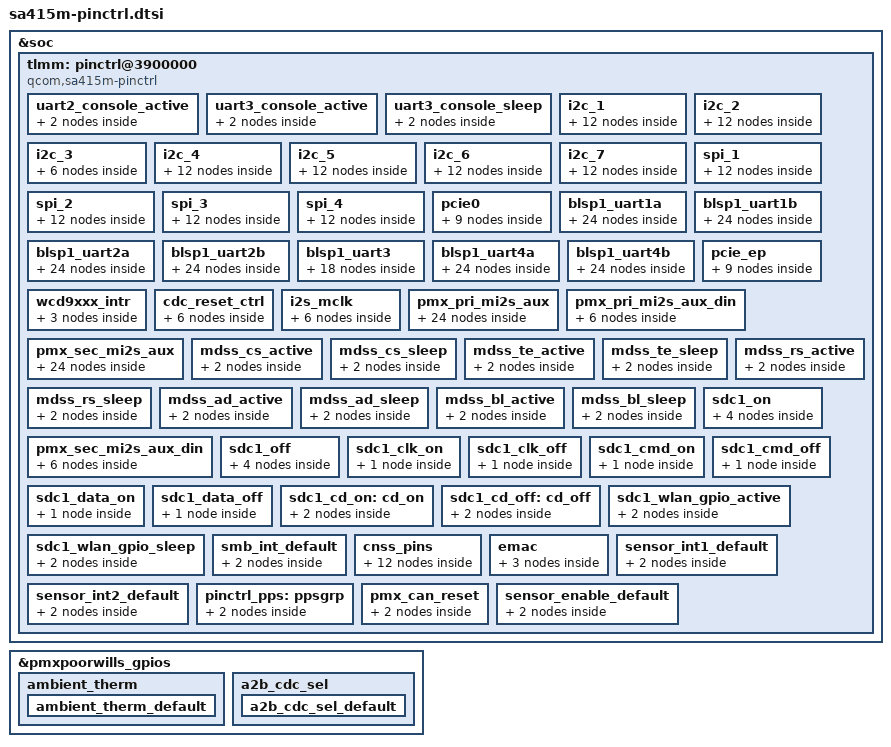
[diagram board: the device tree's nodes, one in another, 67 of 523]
&soc {
	tlmm: pinctrl@3900000 {
		compatible = "qcom,sa415m-pinctrl";
		reg = <0x3900000 0x300000>;
		reg-names = "pinctrl";
		interrupts = <GIC_SPI 212 IRQ_TYPE_LEVEL_HIGH>,
			     <GIC_SPI 213 IRQ_TYPE_LEVEL_HIGH>,
			     <GIC_SPI 214 IRQ_TYPE_LEVEL_HIGH>,
			     <GIC_SPI 215 IRQ_TYPE_LEVEL_HIGH>,
			     <GIC_SPI 216 IRQ_TYPE_LEVEL_HIGH>,
			     <GIC_SPI 217 IRQ_TYPE_LEVEL_HIGH>,
			     <GIC_SPI 218 IRQ_TYPE_LEVEL_HIGH>,
			     <GIC_SPI 219 IRQ_TYPE_LEVEL_HIGH>,
			     <GIC_SPI 220 IRQ_TYPE_LEVEL_HIGH>;
		gpio-controller;
		#gpio-cells = <2>;
		interrupt-controller;
		interrupt-parent = <&intc>;
		#interrupt-cells = <2>;
		wakeup-parent = <&pdc>;

		uart2_console_active: uart2_console_active {
			mux {
				pins = "gpio4", "gpio5";
				function = "blsp_uart2";
			};

			config {
				pins = "gpio4", "gpio5";
				drive-strength = <2>;
				bias-disable;
			};
		};

		uart3_console_active: uart3_console_active {
			mux {
				pins = "gpio8", "gpio9";
				function = "blsp_uart3";
			};

			config {
				pins = "gpio8", "gpio9";
				drive-strength = <2>;
				bias-disable;
			};
		};

		uart3_console_sleep: uart3_console_sleep {
			mux {
				pins = "gpio8", "gpio9";
				function = "gpio";
			};

			config {
				pins = "gpio8", "gpio9";
				drive-strength = <2>;
				bias-disable;
			};
		};

		/* I2C CONFIGURATION */
		i2c_1 {
			i2c_1_sda1_active: i2c_1_sda1_active {
				mux {
					pins = "gpio2";
					function = "blsp_i2c_sda1";
				};

				config {
					pins = "gpio2";
					drive-strength = <2>;
					bias-disable;
				};
			};

			i2c_1_sda1_sleep: i2c_1_sda1_sleep {
				mux {
					pins = "gpio2";
					function = "blsp_i2c_sda1";
				};

				config {
					pins = "gpio2";
					drive-strength = <2>;
					bias-pull-up;
				};
			};

			i2c_1_scl1_active: i2c_1_scl1_active {
				mux {
					pins = "gpio3";
					function = "blsp_i2c_scl1";
				};

				config {
					pins = "gpio3";
					drive-strength = <2>;
					bias-disable;
				};
			};

			i2c_1_scl1_sleep: i2c_1_scl1_sleep {
				mux {
					pins = "gpio3";
					function = "blsp_i2c_scl1";
				};

				config {
					pins = "gpio3";
					drive-strength = <2>;
					bias-pull-up;
				};
			};
		};

		i2c_2 {
			i2c_2_sda2_active: i2c_2_sda2_active {
				mux {
					pins = "gpio6";
					function = "blsp_i2c_sda2";
				};

				config {
					pins = "gpio6";
					drive-strength = <2>;
					bias-disable;
				};
			};

			i2c_2_sda2_sleep: i2c_2_sda2_sleep {
				mux {
					pins = "gpio6";
					function = "blsp_i2c_sda2";
				};

				config {
					pins = "gpio6";
					drive-strength = <2>;
					bias-pull-up;
				};
			};

			i2c_2_scl2_active: i2c_2_scl2_active {
				mux {
					pins = "gpio7";
					function = "blsp_i2c_scl2";
				};

				config {
					pins = "gpio7";
					drive-strength = <2>;
					bias-disable;
				};
			};

			i2c_2_scl2_sleep: i2c_2_scl2_sleep {
				mux {
					pins = "gpio7";
					function = "blsp_i2c_scl2";
				};

				config {
					pins = "gpio7";
					drive-strength = <2>;
					bias-pull-up;
				};
			};
		};

		i2c_3 {
			i2c_3_active: i2c_3_active {
				mux {
					pins = "gpio10", "gpio11";
					function = "blsp_i2c3";
				};

				config {
					pins = "gpio10", "gpio11";
					drive-strength = <2>;
					bias-disable;
				};
			};

			i2c_3_sleep: i2c_3_sleep {
				mux {
					pins = "gpio10", "gpio11";
					function = "blsp_i2c3";
				};

				config {
					pins = "gpio10", "gpio11";
					drive-strength = <2>;
					bias-pull-up;
				};
			};
		};

		i2c_4 {
			i2c_4_sda4_active: i2c_4_sda4_active {
				mux {
					pins = "gpio76";
					function = "blsp_i2c_sda4";
				};

				config {
					pins = "gpio76";
					drive-strength = <2>;
					bias-disable;
				};
			};

			i2c_4_sda4_sleep: i2c_4_sda4_sleep {
				mux {
					pins = "gpio76";
					function = "blsp_i2c_sda4";
				};

				config {
					pins = "gpio76";
					drive-strength = <2>;
					bias-pull-up;
				};
			};

			i2c_4_scl4_active: i2c_4_scl4_active {
				mux {
					pins = "gpio77";
					function = "blsp_i2c_scl4";
				};

				config {
					pins = "gpio77";
					drive-strength = <2>;
					bias-disable;
				};
			};

			i2c_4_scl4_sleep: i2c_4_scl4_sleep {
				mux {
					pins = "gpio77";
					function = "blsp_i2c_scl4";
				};

				config {
					pins = "gpio77";
					drive-strength = <2>;
					bias-pull-up;
				};
			};
		};

		i2c_5 {
			i2c_5_sda1_active: i2c_5_sda1_active {
				mux {
					pins = "gpio74";
					function = "blsp_i2c_sda1";
				};

				config {
					pins = "gpio74";
					drive-strength = <2>;
					bias-disable;
				};
			};

			i2c_5_sda1_sleep: i2c_5_sda1_sleep {
				mux {
					pins = "gpio74";
					function = "blsp_i2c_sda1";
				};

				config {
					pins = "gpio74";
					drive-strength = <2>;
					bias-pull-up;
				};
			};

			i2c_5_scl1_active: i2c_5_scl1_active {
				mux {
					pins = "gpio75";
					function = "blsp_i2c_scl1";
				};

				config {
					pins = "gpio75";
					drive-strength = <2>;
					bias-disable;
				};
			};

			i2c_5_scl1_sleep: i2c_5_scl1_sleep {
				mux {
					pins = "gpio75";
					function = "blsp_i2c_scl1";
				};

				config {
					pins = "gpio75";
					drive-strength = <2>;
					bias-pull-up;
				};
			};
		};

		i2c_6 {
			i2c_6_sda2_active: i2c_6_sda2_active {
				mux {
					pins = "gpio65";
					function = "blsp_i2c_sda2";
				};

				config {
					pins = "gpio65";
					drive-strength = <2>;
					bias-disable;
				};
			};

			i2c_6_sda2_sleep: i2c_6_sda2_sleep {
				mux {
					pins = "gpio65";
					function = "blsp_i2c_sda2";
				};

				config {
					pins = "gpio65";
					drive-strength = <2>;
					bias-pull-up;
				};
			};

			i2c_6_scl2_active: i2c_6_scl2_active {
				mux {
					pins = "gpio66";
					function = "blsp_i2c_scl2";
				};

				config {
					pins = "gpio66";
					drive-strength = <2>;
					bias-disable;
				};
			};

			i2c_6_scl2_sleep: i2c_6_scl2_sleep {
				mux {
					pins = "gpio66";
					function = "blsp_i2c_scl2";
				};

				config {
					pins = "gpio66";
					drive-strength = <2>;
					bias-pull-up;
				};
			};
		};

		i2c_7 {
			i2c_7_sda4_active: i2c_7_sda4_active {
				mux {
					pins = "gpio18";
					function = "blsp_i2c_sda4";
				};

				config {
					pins = "gpio18";
					drive-strength = <2>;
					bias-disable;
				};
			};

			i2c_7_sda4_sleep: i2c_7_sda4_sleep {
				mux {
					pins = "gpio18";
					function = "blsp_i2c_sda4";
				};

				config {
					pins = "gpio18";
					drive-strength = <2>;
					bias-pull-up;
				};
			};

			i2c_7_scl4_active: i2c_7_scl4_active {
				mux {
					pins = "gpio19";
					function = "blsp_i2c_scl4";
				};

				config {
					pins = "gpio19";
					drive-strength = <2>;
					bias-disable;
				};
			};

			i2c_7_scl4_sleep: i2c_7_scl4_sleep {
				mux {
					pins = "gpio19";
					function = "blsp_i2c_scl4";
				};

				config {
					pins = "gpio19";
					drive-strength = <2>;
					bias-pull-up;
				};
			};
		};

		/* SPI CONFIGURATION */
		spi_1 {
			blsp1_active: blsp1_active {
				mux {
					pins = "gpio72", "gpio73",
							"gpio75";
					function = "blsp1";
				};

				config {
					pins = "gpio72", "gpio73",
							"gpio75";
					drive-strength = <6>;
					bias-disable;
				};
			};

			spi_1_cs1_active: spi_1_cs1_active {
				mux {
					pins = "gpio74";
					function = "blsp_spi_cs1";
				};

				config {
					pins = "gpio74";
					drive-strength = <6>;
					bias-disable;
				};
			};

			spi_1_cs1_sleep: spi_1_cs1_sleep {
				mux {
					pins = "gpio74";
					function = "blsp_spi_cs1";
				};

				config {
					pins = "gpio74";
					drive-strength = <6>;
					bias-disable;
				};
			};

			blsp1_sleep: blsp1_sleep {
				mux {
					pins = "gpio72", "gpio73",
							"gpio75";
					function = "blsp1";
				};

				config {
					pins = "gpio72", "gpio73",
							"gpio75";
					drive-strength = <6>;
					bias-disable;
				};
			};
		};

		spi_2 {
			blsp2_active: blsp2_active {
				mux {
					pins = "gpio4", "gpio5",
							"gpio7";
					function = "blsp2";
				};

				config {
					pins = "gpio4", "gpio5",
							"gpio7";
					drive-strength = <6>;
					bias-disable;
				};
			};

			blsp2_sleep: blsp2_sleep {
				mux {
					pins = "gpio4", "gpio5",
							"gpio7";
					function = "blsp2";
				};

				config {
					pins = "gpio4", "gpio5",
							"gpio7";
					drive-strength = <6>;
					bias-disable;
				};
			};

			spi_2_cs2_active: spi_2_cs2_active {
				mux {
					pins = "gpio6";
					function = "blsp_spi_cs2";
				};

				config {
					pins = "gpio6";
					drive-strength = <6>;
					bias-disable;
				};
			};

			spi_2_cs2_sleep: spi_2_cs2_sleep {
				mux {
					pins = "gpio6";
					function = "blsp_spi_cs2";
				};

				config {
					pins = "gpio6";
					drive-strength = <6>;
					bias-disable;
				};
			};
		};

		spi_3 {
			blsp3_active: blsp3_active {
				mux {
					pins = "gpio8", "gpio9",
							"gpio11";
					function = "blsp3";
				};

				config {
					pins = "gpio8", "gpio9",
							"gpio11";
					drive-strength = <6>;
					bias-disable;
				};
			};

			blsp3_sleep: blsp3_sleep {
				mux {
					pins = "gpio8", "gpio9",
							"gpio11";
					function = "blsp3";
				};

				config {
					pins = "gpio8", "gpio9",
							"gpio11";
					drive-strength = <6>;
					bias-disable;
				};
			};

			spi_3_cs3_active: spi_3_cs3_active {
				mux {
					pins = "gpio10";
					function = "blsp_spi_cs3";
				};

				config {
					pins = "gpio10";
					drive-strength = <6>;
					bias-disable;
				};
			};

			spi_3_cs3_sleep: spi_3_cs3_sleep {
				mux {
					pins = "gpio10";
					function = "blsp_spi_cs3";
				};

				config {
					pins = "gpio10";
					drive-strength = <6>;
					bias-disable;
				};
			};
		};

		spi_4 {
			blsp4_active: blsp4_active {
				mux {
					pins = "gpio16", "gpio17",
							"gpio19";
					function = "blsp4";
				};

				config {
					pins = "gpio16", "gpio17",
							"gpio19";
					drive-strength = <6>;
					bias-disable;
				};
			};

			blsp4_sleep: blsp4_sleep {
				mux {
					pins = "gpio16", "gpio17",
							"gpio19";
					function = "blsp4";
				};

				config {
					pins = "gpio16", "gpio17",
							"gpio19";
					drive-strength = <6>;
					bias-disable;
				};
			};

			spi_4_cs4_active: spi_4_cs4_active {
				mux {
					pins = "gpio18";
					function = "blsp_spi_cs4";
				};

				config {
					pins = "gpio18";
					drive-strength = <6>;
					bias-disable;
				};
			};

			spi_4_cs4_sleep: spi_4_cs4_sleep {
				mux {
					pins = "gpio18";
					function = "blsp_spi_cs4";
				};

				config {
					pins = "gpio18";
					drive-strength = <6>;
					bias-disable;
				};
			};
		};

		pcie0 {
			pcie0_clkreq_default: pcie0_clkreq_default {
				mux {
					pins = "gpio56";
					function = "pcie_clkreq";
				};

				config {
					pins = "gpio56";
					drive-strength = <2>;
					bias-pull-up;
				};
			};

			pcie0_perst_default: pcie0_perst_default {
				mux {
					pins = "gpio57";
					function = "gpio";
				};

				config {
					pins = "gpio57";
					drive-strength = <2>;
					bias-pull-down;
				};
			};

			pcie0_wake_default: pcie0_wake_default {
				mux {
					pins = "gpio53";
					function = "gpio";
				};

				config {
					pins = "gpio53";
					drive-strength = <2>;
					bias-pull-up;
				};
			};
		};

		/* HS UART CONFIGURATION */

		blsp1_uart1a: blsp1_uart1a {
			blsp1_uart1a_tx1_active: blsp1_uart1a_tx1_active {
				mux {
					pins = "gpio0";
					function = "blsp_uart_tx1";
				};

				config {
					pins = "gpio0";
					drive-strength = <2>;
					bias-disable;
				};
			};

			blsp1_uart1a_tx1_sleep: blsp1_uart1a_tx1_sleep {
				mux {
					pins = "gpio0";
					function = "blsp_uart_tx1";
				};

				config {
					pins = "gpio0";
					drive-strength = <2>;
					bias-pull-up;
				};
			};

			blsp1_uart1a_rx1_active: blsp1_uart1a_rx1_active {
				mux {
					pins = "gpio1";
					function = "blsp_uart_rx1";
				};

				config {
					pins = "gpio1";
					drive-strength = <2>;
					bias-disable;
				};
			};

			blsp1_uart1a_rx1_sleep: blsp1_uart1a_rx1_sleep {
				mux {
					pins = "gpio1";
					function = "blsp_uart_rx1";
				};

				config {
					pins = "gpio1";
					drive-strength = <2>;
					bias-no-pull;
				};
			};

			blsp1_uart1a_cts1_active: blsp1_uart1a_cts1_active {
				mux {
					pins = "gpio2";
					function = "blsp_uart_cts1";
				};

				config {
					pins = "gpio2";
					drive-strength = <2>;
					bias-disable;
				};
			};

			blsp1_uart1a_cts1_sleep: blsp1_uart1a_cts1_sleep {
				mux {
					pins = "gpio2";
					function = "blsp_uart_cts1";
				};

				config {
					pins = "gpio2";
					drive-strength = <2>;
					bias-no-pull;
				};
			};

			blsp1_uart1a_rfr1_active: blsp1_uart1a_rfr1_active {
				mux {
					pins = "gpio3";
					function = "blsp_uart_rfr1";
				};

				config {
					pins = "gpio3";
					drive-strength = <2>;
					bias-disable;
				};
			};

			blsp1_uart1a_rfr1_sleep: blsp1_uart1a_rfr1_sleep {
				mux {
					pins = "gpio3";
					function = "blsp_uart_rfr1";
				};

				config {
					pins = "gpio3";
					drive-strength = <2>;
					bias-no-pull;
				};
			};
		};

		blsp1_uart1b: blsp1_uart1b {
			blsp1_uart1b_tx1_active: blsp1_uart1b_tx1_active {
				mux {
					pins = "gpio20";
					function = "blsp_uart_tx1";
				};

				config {
					pins = "gpio20";
					drive-strength = <2>;
					bias-disable;
				};
			};

			blsp1_uart1b_tx1_sleep: blsp1_uart1b_tx1_sleep {
				mux {
					pins = "gpio20";
					function = "blsp_uart_tx1";
				};

				config {
					pins = "gpio20";
					drive-strength = <2>;
					bias-pull-up;
				};
			};

			blsp1_uart1b_rx1_active: blsp1_uart1b_rx1_active {
				mux {
					pins = "gpio21";
					function = "blsp_uart_rx1";
				};

				config {
					pins = "gpio21";
					drive-strength = <2>;
					bias-disable;
				};
			};

			blsp1_uart1b_rx1_sleep: blsp1_uart1b_rx1_sleep {
				mux {
					pins = "gpio21";
					function = "blsp_uart_rx1";
				};

				config {
					pins = "gpio21";
					drive-strength = <2>;
					bias-no-pull;
				};
			};

			blsp1_uart1b_cts1_active: blsp1_uart1b_cts1_active {
				mux {
					pins = "gpio22";
					function = "blsp_uart_cts1";
				};

				config {
					pins = "gpio22";
					drive-strength = <2>;
					bias-disable;
				};
			};

			blsp1_uart1b_cts1_sleep: blsp1_uart1b_cts1_sleep {
				mux {
					pins = "gpio22";
					function = "blsp_uart_cts1";
				};

				config {
					pins = "gpio22";
					drive-strength = <2>;
					bias-no-pull;
				};
			};

			blsp1_uart1b_rfr1_active: blsp1_uart1b_rfr1_active {
				mux {
					pins = "gpio23";
					function = "blsp_uart_rfr1";
				};

				config {
					pins = "gpio23";
					drive-strength = <2>;
					bias-disable;
				};
			};

			blsp1_uart1b_rfr1_sleep: blsp1_uart1b_rfr1_sleep {
				mux {
					pins = "gpio23";
					function = "blsp_uart_rfr1";
				};

				config {
					pins = "gpio23";
					drive-strength = <2>;
					bias-no-pull;
				};
			};
		};

		blsp1_uart2a: blsp1_uart2a {
			blsp1_uart2a_tx2_active: blsp1_uart2a_tx2_active {
				mux {
					pins = "gpio4";
					function = "blsp_uart_tx2";
				};

				config {
					pins = "gpio4";
					drive-strength = <2>;
					bias-disable;
				};
			};

			blsp1_uart2a_tx2_sleep: blsp1_uart2a_tx2_sleep {
				mux {
					pins = "gpio4";
					function = "blsp_uart_tx2";
				};

				config {
					pins = "gpio4";
					drive-strength = <2>;
					bias-pull-up;
				};
			};

			blsp1_uart2a_rx2_active: blsp1_uart2a_rx2_active {
				mux {
					pins = "gpio5";
					function = "blsp_uart_rx2";
				};

				config {
					pins = "gpio5";
					drive-strength = <2>;
					bias-disable;
				};
			};

			blsp1_uart2a_rx2_sleep: blsp1_uart2a_rx2_sleep {
				mux {
					pins = "gpio5";
					function = "blsp_uart_rx2";
				};

				config {
					pins = "gpio5";
					drive-strength = <2>;
					bias-disable;
				};
			};

			blsp1_uart2a_cts2_active: blsp1_uart2a_cts2_active {
				mux {
					pins = "gpio6";
					function = "blsp_uart_cts2";
				};

				config {
					pins = "gpio6";
					drive-strength = <2>;
					bias-disable;
				};
			};

			blsp1_uart2a_cts2_sleep: blsp1_uart2a_cts2_sleep {
				mux {
					pins = "gpio6";
					function = "blsp_uart_cts2";
				};

				config {
					pins = "gpio6";
					drive-strength = <2>;
					bias-no-pull;
				};
			};

			blsp1_uart2a_rfr2_active: blsp1_uart2a_rfr2_active {
				mux {
					pins = "gpio7";
					function = "blsp_uart_rfr2";
				};

				config {
					pins = "gpio7";
					drive-strength = <2>;
					bias-disable;
				};
			};

			blsp1_uart2a_rfr2_sleep: blsp1_uart2a_rfr2_sleep {
				mux {
					pins = "gpio7";
					function = "blsp_uart_rfr2";
				};

				config {
					pins = "gpio7";
					drive-strength = <2>;
					bias-no-pull;
				};
			};
		};

		blsp1_uart2b: blsp1_uart2b {
			blsp1_uart2b_tx2_active: blsp1_uart2b_tx2_active {
				mux {
					pins = "gpio63";
					function = "blsp_uart_tx2";
				};

				config {
					pins = "gpio63";
					drive-strength = <2>;
					bias-disable;
				};
			};

			blsp1_uart2b_tx2_sleep: blsp1_uart2b_tx2_sleep {
				mux {
					pins = "gpio63";
					function = "blsp_uart_tx2";
				};

				config {
					pins = "gpio63";
					drive-strength = <2>;
					bias-pull-up;
				};
			};

			blsp1_uart2b_rx2_active: blsp1_uart2b_rx2_active {
				mux {
					pins = "gpio64";
					function = "blsp_uart_rx2";
				};

				config {
					pins = "gpio64";
					drive-strength = <2>;
					bias-disable;
				};
			};

			blsp1_uart2b_rx2_sleep: blsp1_uart2b_rx2_sleep {
				mux {
					pins = "gpio64";
					function = "blsp_uart_rx2";
				};

				config {
					pins = "gpio64";
					drive-strength = <2>;
					bias-no-pull;
				};
			};

			blsp1_uart2b_cts2_active: blsp1_uart2b_cts2_active {
				mux {
					pins = "gpio65";
					function = "blsp_uart_cts2";
				};

				config {
					pins = "gpio65";
					drive-strength = <2>;
					bias-disable;
				};
			};

			blsp1_uart2b_cts2_sleep: blsp1_uart2b_cts2_sleep {
				mux {
					pins = "gpio65";
					function = "blsp_uart_cts2";
				};

				config {
					pins = "gpio65";
					drive-strength = <2>;
					bias-no-pull;
				};
			};

			blsp1_uart2b_rfr2_active: blsp1_uart2b_rfr2_active {
				mux {
					pins = "gpio66";
					function = "blsp_uart_rfr2";
				};

				config {
					pins = "gpio66";
					drive-strength = <2>;
					bias-disable;
				};
			};

			blsp1_uart2b_rfr2_sleep: blsp1_uart2b_rfr2_sleep {
				mux {
					pins = "gpio66";
					function = "blsp_uart_rfr2";
				};

				config {
					pins = "gpio66";
					drive-strength = <2>;
					bias-no-pull;
				};
			};
		};

		blsp1_uart3: blsp1_uart3 {
			blsp1_uart3_tx_active: blsp1_uart3_tx_active {
				mux {
					pins = "gpio8";
					function = "blsp_uart3";
				};

				config {
					pins = "gpio8";
					drive-strength = <2>;
					bias-disable;
				};
			};

			blsp1_uart3_tx_sleep: blsp1_uart3_tx_sleep {
				mux {
					pins = "gpio8";
					function = "gpio";
				};

				config {
					pins = "gpio8";
					drive-strength = <2>;
					bias-pull-up;
				};
			};

			blsp1_uart3_rxcts_active: blsp1_uart3_rxcts_active {
				mux {
					pins = "gpio9", "gpio10";
					function = "blsp_uart3";
				};

				config {
					pins = "gpio9", "gpio10";
					drive-strength = <2>;
					bias-disable;
				};
			};

			blsp1_uart3_rxcts_sleep: blsp1_uart3_rxcts_sleep {
				mux {
					pins = "gpio9", "gpio10";
					function = "gpio";
				};

				config {
					pins = "gpio9", "gpio10";
					drive-strength = <2>;
					bias-no-pull;
				};
			};

			blsp1_uart3_rfr_active: blsp1_uart3_rfr_active {
				mux {
					pins = "gpio11";
					function = "blsp_uart3";
				};

				config {
					pins = "gpio11";
					drive-strength = <2>;
					bias-disable;
				};
			};

			blsp1_uart3_rfr_sleep: blsp1_uart3_rfr_sleep {
				mux {
					pins = "gpio11";
					function = "gpio";
				};

				config {
					pins = "gpio11";
					drive-strength = <2>;
					bias-no-pull;
				};
			};
		};

		blsp1_uart4a: blsp1_uart4a {
			blsp1_uart4a_tx4_active: blsp1_uart4a_tx4_active {
				mux {
					pins = "gpio20";
					function = "blsp_uart_tx4";
				};

				config {
					pins = "gpio20";
					drive-strength = <2>;
					bias-disable;
				};
			};

			blsp1_uart4a_tx4_sleep: blsp1_uart4a_tx4_sleep {
				mux {
					pins = "gpio20";
					function = "blsp_uart_tx4";
				};

				config {
					pins = "gpio20";
					drive-strength = <2>;
					bias-pull-up;
				};
			};

			blsp1_uart4a_rx4_active: blsp1_uart4a_rx4_active {
				mux {
					pins = "gpio21";
					function = "blsp_uart_rx4";
				};

				config {
					pins = "gpio21";
					drive-strength = <2>;
					bias-disable;
				};
			};

			blsp1_uart4a_rx4_sleep: blsp1_uart4a_rx4_sleep {
				mux {
					pins = "gpio21";
					function = "blsp_uart_rx4";
				};

				config {
					pins = "gpio21";
					drive-strength = <2>;
					bias-no-pull;
				};
			};

			blsp1_uart4a_cts4_active: blsp1_uart4a_cts4_active {
				mux {
					pins = "gpio22";
					function = "blsp_uart_cts4";
				};

				config {
					pins = "gpio22";
					drive-strength = <2>;
					bias-disable;
				};
			};

			blsp1_uart4a_cts4_sleep: blsp1_uart4a_cts4_sleep {
				mux {
					pins = "gpio22";
					function = "blsp_uart_cts4";
				};

				config {
					pins = "gpio22";
					drive-strength = <2>;
					bias-no-pull;
				};
			};

			blsp1_uart4a_rfr4_active: blsp1_uart4a_rfr4_active {
				mux {
					pins = "gpio23";
					function = "blsp_uart_rfr4";
				};

				config {
					pins = "gpio23";
					drive-strength = <2>;
					bias-disable;
				};
			};

			blsp1_uart4a_rfr4_sleep: blsp1_uart4a_rfr4_sleep {
				mux {
					pins = "gpio23";
					function = "blsp_uart_rfr4";
				};

				config {
					pins = "gpio23";
					drive-strength = <2>;
					bias-no-pull;
				};
			};
		};

		blsp1_uart4b: blsp1_uart4b {
			blsp1_uart4b_tx4_active: blsp1_uart4b_tx4_active {
				mux {
					pins = "gpio16";
					function = "blsp_uart_tx4";
				};

				config {
					pins = "gpio16";
					drive-strength = <2>;
					bias-disable;
				};
			};

			blsp1_uart4b_tx4_sleep: blsp1_uart4b_tx4_sleep {
				mux {
					pins = "gpio16";
					function = "blsp_uart_tx4";
				};

				config {
					pins = "gpio16";
					drive-strength = <2>;
					bias-pull-up;
				};
			};

			blsp1_uart4b_rx4_active: blsp1_uart4b_rx4_active {
				mux {
					pins = "gpio17";
					function = "blsp_uart_rx4";
				};

				config {
					pins = "gpio17";
					drive-strength = <2>;
					bias-disable;
				};
			};

			blsp1_uart4b_rx4_sleep: blsp1_uart4b_rx4_sleep {
				mux {
					pins = "gpio17";
					function = "blsp_uart_rx4";
				};

				config {
					pins = "gpio17";
					drive-strength = <2>;
					bias-disable;
				};
			};

			blsp1_uart4b_cts4_active: blsp1_uart4b_cts4_active {
				mux {
					pins = "gpio18";
					function = "blsp_uart_cts4";
				};

				config {
					pins = "gpio18";
					drive-strength = <2>;
					bias-no-pull;
				};
			};

			blsp1_uart4b_cts4_sleep: blsp1_uart4b_cts4_sleep {
				mux {
					pins = "gpio18";
					function = "blsp_uart_cts4";
				};

				config {
					pins = "gpio18";
					drive-strength = <2>;
					bias-no-pull;
				};
			};

			blsp1_uart4b_rfr4_active: blsp1_uart4b_rfr4_active {
				mux {
					pins = "gpio19";
					function = "blsp_uart_rfr4";
				};

				config {
					pins = "gpio19";
					drive-strength = <2>;
					bias-disable;
				};
			};

			blsp1_uart4b_rfr4_sleep: blsp1_uart4b_rfr4_sleep {
				mux {
					pins = "gpio19";
					function = "blsp_uart_rfr4";
				};

				config {
					pins = "gpio19";
					drive-strength = <2>;
					bias-no-pull;
				};
			};
		};

		pcie_ep {
			pcie_ep_clkreq_default: pcie_ep_clkreq_default {
				mux {
					pins = "gpio56";
					function = "pcie_clkreq";
				};

				config {
					pins = "gpio56";
					drive-strength = <2>;
					bias-disable;
				};
			};

			pcie_ep_perst_default: pcie_ep_perst_default {
				mux {
					pins = "gpio57";
					function = "gpio";
				};

				config {
					pins = "gpio57";
					drive-strength = <2>;
					bias-pull-down;
				};
			};

			pcie_ep_wake_default: pcie_ep_wake_default {
				mux {
					pins = "gpio53";
					function = "gpio";
				};

				config {
					pins = "gpio53";
					drive-strength = <2>;
					bias-disable;
				};
			};
		};

		wcd9xxx_intr {
			wcd_intr_default: wcd_intr_default {
				mux {
					pins = "gpio90";
					function = "gpio";
				};

				config {
					pins = "gpio90";
					drive-strength = <2>; /* 2 mA */
					bias-pull-down; /* pull down */
					input-enable;
				};
			};
		};

		cdc_reset_ctrl {
			cdc_reset_sleep: cdc_reset_sleep {
				mux {
					pins = "gpio86";
					function = "gpio";
				};

				config {
					pins = "gpio86";
					drive-strength = <2>;
					bias-disable;
					output-low;
				};
			};

			cdc_reset_active:cdc_reset_active {
				mux {
					pins = "gpio86";
					function = "gpio";
				};

				config {
					pins = "gpio86";
					drive-strength = <8>;
					bias-pull-down;
					output-high;
				};
			};
		};

		i2s_mclk {
			i2s_mclk_sleep: i2s_mclk_sleep {
				mux {
					pins = "gpio62";
					function = "i2s_mclk";
				};

				config {
					pins = "gpio62";
					drive-strength = <2>;	/* 2 mA */
					bias-pull-down;		/* PULL DOWN */
				};
			};

			i2s_mclk_active: i2s_mclk_active {
				mux {
					pins = "gpio62";
					function = "i2s_mclk";
				};

				config {
					pins = "gpio62";
					drive-strength = <8>;	/* 8 mA */
					bias-disable;		/* NO PULL*/
					output-high;
				};
			};
		};

		pmx_pri_mi2s_aux {
			pri_ws_sleep: pri_ws_sleep {
				mux {
					pins = "gpio12";
					function = "gpio";
				};

				config {
					pins = "gpio12";
					drive-strength = <2>;	/* 2 mA */
					bias-pull-down;		/* PULL DOWN */
					input-enable;
				};
			};

			pri_sck_sleep: pri_sck_sleep {
				mux {
					pins = "gpio15";
					function = "gpio";
				};

				config {
					pins = "gpio15";
					drive-strength = <2>;	/* 2 mA */
					bias-pull-down;		/* PULL DOWN */
					input-enable;
				};
			};

			pri_dout_sleep: pri_dout_sleep {
				mux {
					pins = "gpio14";
					function = "gpio";
				};

				config {
					pins = "gpio14";
					drive-strength = <2>;	/* 2 mA */
					bias-pull-down;		/* PULL DOWN */
					input-enable;
				};
			};

			pri_ws_active_master: pri_ws_active_master {
				mux {
					pins = "gpio12";
					function = "pri_mi2s_ws";
				};

				config {
					pins = "gpio12";
					drive-strength = <8>;	/* 8 mA */
					bias-disable;		/* NO PULL*/
					output-high;
				};
			};

			pri_sck_active_master: pri_sck_active_master {
				mux {
					pins = "gpio15";
					function = "pri_mi2s_sck";
				};

				config {
					pins = "gpio15";
					drive-strength = <8>;	/* 8 mA */
					bias-disable;		/* NO PULL*/
					output-high;
				};
			};

			pri_ws_active_slave: pri_ws_active_slave {
				mux {
					pins = "gpio12";
					function = "pri_mi2s_ws";
				};

				config {
					pins = "gpio12";
					drive-strength = <8>;	/* 8 mA */
					bias-disable;		/* NO PULL*/
				};
			};

			pri_sck_active_slave: pri_sck_active_slave {
				mux {
					pins = "gpio15";
					function = "pri_mi2s_sck";
				};

				config {
					pins = "gpio15";
					drive-strength = <8>;	/* 8 mA */
					bias-disable;		/* NO PULL*/
				};
			};

			pri_dout_active: pri_dout_active {
				mux {
					pins = "gpio14";
					function = "pri_mi2s_data1";
				};

				config {
					pins = "gpio14";
					drive-strength = <8>;	/* 8 mA */
					bias-disable;		/* NO PULL*/
					output-high;
				};
			};
		};

		pmx_pri_mi2s_aux_din {
			pri_din_sleep: pri_din_sleep {
				mux {
					pins = "gpio13";
					function = "gpio";
				};

				config {
					pins = "gpio13";
					drive-strength = <2>;	/* 2 mA */
					bias-pull-down;		/* PULL DOWN */
					input-enable;
				};
			};

			pri_din_active: pri_din_active {
				mux {
					pins = "gpio13";
					function = "pri_mi2s_data0";
				};

				config {
					pins = "gpio13";
					drive-strength = <8>;	/* 8 mA */
					bias-disable;		/* NO PULL */
				};
			};
		};

		pmx_sec_mi2s_aux {
			sec_ws_sleep: sec_ws_sleep {
				mux {
					pins = "gpio16";
					function = "gpio";
				};

				config {
					pins = "gpio16";
					drive-strength = <2>;	/* 2 mA */
					bias-pull-down;		/* PULL DOWN */
					input-enable;
				};
			};

			sec_sck_sleep: sec_sck_sleep {
				mux {
					pins = "gpio19";
					function = "gpio";
				};

				config {
					pins = "gpio19";
					drive-strength = <2>;	/* 2 mA */
					bias-pull-down;		/* PULL DOWN */
					input-enable;
				};
			};

			sec_dout_sleep: sec_dout_sleep {
				mux {
					pins = "gpio18";
					function = "gpio";
				};

				config {
					pins = "gpio18";
					drive-strength = <2>;	/* 2 mA */
					bias-pull-down;		/* PULL DOWN */
					input-enable;
				};
			};

			sec_ws_active_master: sec_ws_active_master {
				mux {
					pins = "gpio16";
					function = "sec_mi2s_ws";
				};

				config {
					pins = "gpio16";
					drive-strength = <8>;	/* 8 mA */
					bias-disable;		/* NO PULL*/
					output-high;
				};
			};

			sec_sck_active_master: sec_sck_active_master {
				mux {
					pins = "gpio19";
					function = "sec_mi2s_sck";
				};

				config {
					pins = "gpio19";
					drive-strength = <8>;	/* 8 mA */
					bias-disable;		/* NO PULL*/
					output-high;
				};
			};

			sec_ws_active_slave: sec_ws_active_slave {
				mux {
					pins = "gpio16";
					function = "sec_mi2s_ws";
				};

				config {
					pins = "gpio16";
					drive-strength = <8>;	/* 8 mA */
					bias-disable;		/* NO PULL*/
				};
			};

			sec_sck_active_slave: sec_sck_active_slave {
				mux {
					pins = "gpio19";
					function = "sec_mi2s_sck";
				};

				config {
					pins = "gpio19";
					drive-strength = <8>;	/* 8 mA */
					bias-disable;		/* NO PULL*/
				};
			};

			sec_dout_active: sec_dout_active {
				mux {
					pins = "gpio18";
					function = "sec_mi2s_data1";
				};

				config {
					pins = "gpio18";
					drive-strength = <8>;	/* 8 mA */
					bias-disable;		/* NO PULL*/
					output-high;
				};
			};
		};

		mdss_cs_active: mdss_cs_active {
			mux {
					pins = "gpio21";
					function = "ebi2_lcd";
			};

			config {
					pins = "gpio21";
					drive-strength = <10>; /* 10 mA */
					bias-disable; /* NO pull */
			};
		};

		mdss_cs_sleep: mdss_cs_sleep {
			mux {
					pins = "gpio21";
					function = "ebi2_lcd";
			};

			config {
					pins = "gpio21";
					drive-strength = <2>; /* 2 mA */
					bias-disable; /* NO pull */
			};
		};

		mdss_te_active: mdss_te_active {
			mux {
					pins = "gpio22";
					function = "ebi2_lcd";
			};

			config {
					pins = "gpio22";
					drive-strength = <10>; /* 10 mA */
					bias-disable; /* NO pull */
			};
		};

		mdss_te_sleep: mdss_te_sleep {
			mux {
					pins = "gpio22";
					function = "ebi2_lcd";
			};

			config {
					pins = "gpio22";
					drive-strength = <2>; /* 2 mA */
					bias-disable; /* NO pull */
			};
		};

		mdss_rs_active: mdss_rs_active {
			mux {
					pins = "gpio23";
					function = "ebi2_lcd";
			};

			config {
					pins = "gpio23";
					drive-strength = <10>; /* 10 mA */
					bias-disable; /* NO pull */
			};
		};

		mdss_rs_sleep: mdss_rs_sleep {
			mux {
					pins = "gpio23";
					function = "ebi2_lcd";
			};

			config {
					pins = "gpio23";
					drive-strength = <2>; /* 2 mA */
					bias-disable; /* NO pull */
			};
		};

		mdss_ad_active: mdss_ad_active {
			mux {
					pins = "gpio20";
					function = "ebi2_a";
			};

			config {
					pins = "gpio20";
					drive-strength = <10>; /* 10 mA */
					bias-disable; /* NO pull */
			};
		};

		mdss_ad_sleep: mdss_ad_sleep {
			mux {
					pins = "gpio20";
					function = "ebi2_a";
			};

			config {
					pins = "gpio20";
					drive-strength = <2>; /* 2 mA */
					bias-disable; /* NO pull */
			};
		};

		mdss_bl_active: mdss_bl_active {
			mux {
					pins = "gpio91";
					function = "gpio";
			};

			config {
					pins = "gpio91";
					drive-strength = <10>; /* 10 mA */
					bias-disable; /* NO pull */
					output-high;
			};
		};

		mdss_bl_sleep: mdss_bl_sleep {
			mux {
					pins = "gpio91";
					function = "gpio";
			};

			config {
					pins = "gpio91";
					drive-strength = <2>; /* 2 mA */
					bias-disable; /* NO pull */
					output-low;
			};
		};

		pmx_sec_mi2s_aux_din {
			sec_din_sleep: sec_din_sleep {
				mux {
					pins = "gpio17";
					function = "gpio";
				};

				config {
					pins = "gpio17";
					drive-strength = <2>;	/* 2 mA */
					bias-pull-down;		/* PULL DOWN */
					input-enable;
				};
			};

			sec_din_active: sec_din_active {
				mux {
					pins = "gpio17";
					function = "sec_mi2s_data0";
				};

				config {
					pins = "gpio17";
					drive-strength = <8>;	/* 8 mA */
					bias-disable;		/* NO PULL */
				};
			};
		};

		/* SDC pin type */

		sdc1_on: sdc1_on {
			clk {
				pins = "sdc1_clk";
				bias-disable;
				drive-strength = <16>;
			};

			cmd {
				pins = "sdc1_cmd";
				bias-pull-up;
				drive-strength = <10>;
			};

			data {
				pins = "sdc1_data";
				bias-pull-up;
				drive-strength = <10>;
			};

			sd-cd {
				pins = "gpio93";
				bias-pull-up;
				drive-strength = <2>;
			};
		};

		sdc1_off: sdc1_off {
			clk {
				pins = "sdc1_clk";
				bias-disable;
				drive-strength = <2>;
			};

			cmd {
				pins = "sdc1_cmd";
				bias-pull-up;
				drive-strength = <2>;
			};

			data {
				pins = "sdc1_data";
				bias-pull-up;
				drive-strength = <2>;
			};

			sd-cd {
				pins = "gpio93";
				bias-disable;
				drive-strength = <2>;
			};
		};

		sdc1_clk_on: sdc1_clk_on {
			config {
				pins = "sdc1_clk";
				bias-disable;		/* NO pull */
				drive-strength = <16>;	/* 16 MA */
			};
		};

		sdc1_clk_off: sdc1_clk_off {
			config {
				pins = "sdc1_clk";
				bias-disable;		/* NO pull */
				drive-strength = <2>;	/* 2 MA */
			};
		};

		sdc1_cmd_on: sdc1_cmd_on {
			config {
				pins = "sdc1_cmd";
				bias-pull-up;		/* pull up */
				drive-strength = <10>;	/* 10 MA */
			};
		};

		sdc1_cmd_off: sdc1_cmd_off {
			config {
				pins = "sdc1_cmd";
				num-grp-pins = <1>;
				bias-pull-up;		/* pull up */
				drive-strength = <2>;	/* 2 MA */
			};
		};

		sdc1_data_on: sdc1_data_on {
			config {
				pins = "sdc1_data";
				bias-pull-up;		/* pull up */
				drive-strength = <10>;	/* 10 MA */
			};
		};

		sdc1_data_off: sdc1_data_off {
			config {
				pins = "sdc1_data";
				bias-pull-up;		/* pull up */
				drive-strength = <2>;	/* 2 MA */
			};
		};

		sdc1_cd_on: cd_on {
			mux {
				pins = "gpio93";
				function = "gpio";
			};

			config {
				pins = "gpio93";
				drive-strength = <2>;
				bias-pull-up;
			};
		};

		sdc1_cd_off: cd_off {
			mux {
				pins = "gpio93";
				function = "gpio";
			};

			config {
				pins = "gpio93";
				drive-strength = <2>;
				bias-disable;
			};
		};

		sdc1_wlan_gpio_active: sdc1_wlan_gpio_active {
			mux {
				pins = "gpio81";
				function = "gpio";
			};

			config {
				pins = "gpio81";
				output-high;
				drive-strength = <8>;
				bias-pull-up;
			};
		};

		sdc1_wlan_gpio_sleep: sdc1_wlan_gpio_sleep {
			mux {
				pins = "gpio81";
				function = "gpio";
			};

			config {
				pins = "gpio81";
				drive-strength = <2>;
				bias-pull-down;
				output-low;
			};
		};

		smb_int_default: smb_int_default {
			mux {
				pins = "gpio42";
				function = "gpio";
			};

			config {
				pins = "gpio42";
				drive-strength = <2>;
				bias-pull-up;
				input-enable;
			};
		};

		cnss_pins {
			cnss_wlan_en_active: cnss_wlan_en_active {
				mux {
					pins = "gpio52";
					function = "gpio";
				};

				config {
					pins = "gpio52";
					drive-strength = <16>;
					output-high;
					bias-pull-up;
				};
			};

			cnss_wlan_en_sleep: cnss_wlan_en_sleep {
				mux {
					pins = "gpio52";
					function = "gpio";
				};

				config {
					pins = "gpio52";
					drive-strength = <2>;
					output-low;
					bias-pull-down;
				};
			};

			cnss_sdio_active: cnss_sdio_active {
				mux {
					pins = "gpio31";
					function = "gpio";
				};

				config {
					pins = "gpio31";
					drive-strength = <16>;
					output-high;
					bias-pull-up;
				};
			};

			cnss_sdio_sleep: cnss_sdio_sleep {
				mux {
					pins = "gpio31";
					function = "gpio";
				};

				config {
					pins = "gpio31";
					drive-strength = <2>;
					output-low;
					bias-pull-down;
				};
			};
		};

		emac {
			emac_pin_pps_0: emac_pin_pps_0 {
				mux {
					pins = "gpio89";
					function = "emac_pps";
				};

				config {
					pins = "gpio89";
					drive-strength = <8>;	/* 8 mA */
					bias-disable;		/* NO PULL*/
				};
			};
		};

		sensor_int1_default: sensor_int1_default {
			     mux {
				     pins = "gpio78";
				     function = "gpio";
			     };

			     config {
				     pins = "gpio78";
				     drive-strength = <16>; /* 16 mA */
				     bias-pull-down; /* pull down */
			     };
		};

		sensor_int2_default: sensor_int2_default {
			     mux {
				     pins = "gpio79";
				     function = "gpio";
			     };

			     config {
				     pins = "gpio79";
				     drive-strength = <16>; /* 16 mA */
				     bias-pull-down; /* pull down */
			     };
		};

		pinctrl_pps: ppsgrp {
			mux {
				pins = "gpio42";
				function = "nav_dr";
			};

			config {
				pins = "gpio42";
				bias-pull-down;
			};
		};

		pmx_can_reset: pmx_can_reset {
			mux {
				pins = "gpio99";
				function = "gpio";
			};

			config {
				pins = "gpio99";
				drive-strength = <2>;
				bias-disable;
				output-high;
			};
		};

		sensor_enable_default: sensor_enable_default {
			mux {
				pins = "gpio90";
				function = "gpio";
			};

			config {
				pins = "gpio90";
				bias-pull-up;
				drive-strength = <16>;
				output-low;
			};
		};
	};
};

&pmxpoorwills_gpios {
	ambient_therm {
		ambient_therm_default: ambient_therm_default {
			pins = "gpio2";
			bias-high-impedance;
		};
	};

	a2b_cdc_sel {
		a2b_cdc_sel_default: a2b_cdc_sel_default {
			pins = "gpio5";
			power-source = <1>;
			output-high;
		};
	};
};
